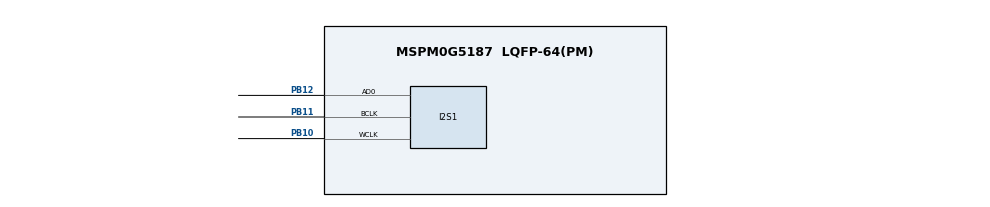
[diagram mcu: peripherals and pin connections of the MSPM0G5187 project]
//@cliArgs --device "MSPM0G518X" --package "LQFP-64(PM)" --part "Default"
//@v2CliArgs --device "MSPM0G5187" --package "LQFP-64(PM)"
// @cliArgs --board /ti/boards/LP_MSPM0G5187 --rtos nortos

/**
 * Import the modules used in this configuration.
 */
const DMA     = scripting.addModule("/ti/driverlib/DMA");
const I2S     = scripting.addModule("/ti/driverlib/I2S", {}, false);
const I2S1    = I2S.addInstance();
const SYSCTL  = scripting.addModule("/ti/driverlib/SYSCTL");
const SYSTICK = scripting.addModule("/ti/driverlib/SYSTICK");
const UART    = scripting.addModule("/ti/driverlib/UART", {}, false);
const UART1   = UART.addInstance();
const tinyusb = scripting.addModule("/ti/tinyusb_meta/tinyusb");

/**
 * Write custom configuration values to the imported modules.
 */
const divider9       = system.clockTree["UDIV"];
divider9.divideValue = 2;

const gate10           = system.clockTree["USBFLLGATE"];
gate10.enable          = true;
gate10.referenceSource = "SOF";

const multiplier2         = system.clockTree["PLL_QDIV"];
multiplier2.multiplyValue = 5;

const mux7       = system.clockTree["HSCLKMUX"];
mux7.inputSelect = "HSCLKMUX_SYSPLL0";

const Board = scripting.addModule("/ti/driverlib/Board", {}, false);

I2S1.$name                                 = "I2S_0";
I2S1.phase                                 = "DUAL";
I2S1.dataDelay                             = "ONE";
I2S1.memoryAccessLength                    = "32";
I2S1.dataPin0Enable                        = true;
I2S1.wordBaudClockSource                   = "INTERNAL";
I2S1.enabledDMAEvent1Triggers              = "DL_I2S_DMA_INTERRUPT_RX_TRIGGER";
I2S1.enableFreeRun                         = true;
I2S1.enabledInterrupts                     = ["DMA_DONE_RX"];
I2S1.wclkDivider                           = 48;
I2S1.bclkDivider                           = 7;
I2S1.wclkPhase                             = "DUAL";
I2S1.wclkInvert                            = true;
I2S1.sampleWordLength                      = 25;
I2S1.samplingEdge                          = "POS";
I2S1.peripheral.AD0Pin.$assign             = "PB12";
I2S1.peripheral.BCLKPin.$assign            = "PB11";
I2S1.peripheral.WCLKPin.$assign            = "PB10";
I2S1.DMA_CHANNEL_EVENT1.$name              = "DMA_CH0";
I2S1.DMA_CHANNEL_EVENT1.addressMode        = "f2b";
I2S1.DMA_CHANNEL_EVENT1.transferMode       = "FULL_CH_REPEAT_SINGLE";
I2S1.DMA_CHANNEL_EVENT1.peripheral.$assign = "DMA_CH0";

SYSCTL.forceDefaultClkConfig = true;
SYSCTL.clockTreeEn           = true;
scripting.suppress("For best practices when the CPUCLK is running at 32MHz and above, clear the flash status bit using DL_FlashCTL_executeClearStatus\\(\\) before executing any flash operation\\. Otherwise there may be false positives\\.", SYSCTL);

SYSTICK.periodEnable    = true;
SYSTICK.period          = 80000;
SYSTICK.interruptEnable = true;
SYSTICK.systickEnable   = true;

tinyusb.generateDescriptors                                      = false;
tinyusb.associated_USB.$name                                     = "USB_0";
tinyusb.associatedGPIO_LED.$name                                 = "GPIO_GRP_0";
tinyusb.associatedGPIO_LED.port                                  = "PORTA";
tinyusb.associatedGPIO_LED.portSegment                           = "Upper";
tinyusb.associatedGPIO_LED.associatedPins[0].$name               = "PIN_0";
tinyusb.associatedGPIO_LED.associatedPins[0].assignedPin         = "24";
tinyusb.associatedGPIO_BUTTON.$name                              = "GPIO_GRP_1";
tinyusb.associatedGPIO_BUTTON.port                               = "PORTA";
tinyusb.associatedGPIO_BUTTON.portSegment                        = "Lower";
tinyusb.associatedGPIO_BUTTON.associatedPins[0].$name            = "PIN_1";
tinyusb.associatedGPIO_BUTTON.associatedPins[0].internalResistor = "PULL_UP";
tinyusb.associatedGPIO_BUTTON.associatedPins[0].assignedPin      = "7";
tinyusb.associatedGPIO_BUTTON.associatedPins[0].direction        = "INPUT";

UART1.$name             = "UART_0";
UART1.targetBaudRate    = 115200;
tinyusb.associatedUART  = UART1;
